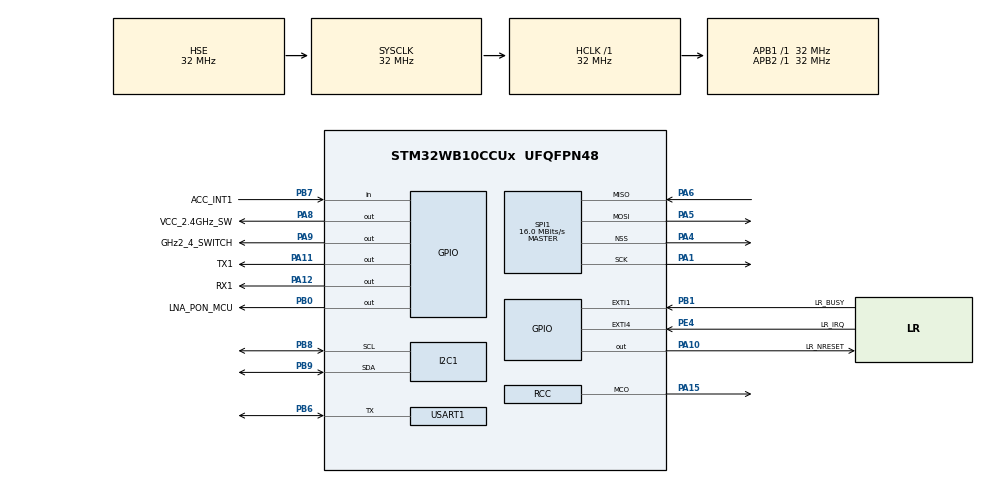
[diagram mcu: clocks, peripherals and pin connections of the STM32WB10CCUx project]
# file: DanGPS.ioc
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ADC1.Channel-0\#ChannelRegularConversion=ADC_CHANNEL_VBAT
ADC1.NbrOfConversionFlag=1
ADC1.Rank-0\#ChannelRegularConversion=1
ADC1.SamplingTime-0\#ChannelRegularConversion=ADC_SAMPLINGTIME_COMMON_1
ADC1.SelectedChannel=ADC_CHANNEL_TEMPSENSOR|ADC_CHANNEL_VBAT
ADC1.master=1
AES2.Algorithm=CRYP_AES_CCM
I2C1.Timing=0x00707CBB
Mcu.Family=STM32WB
Mcu.Name=STM32WB10CCUx
Mcu.Package=UFQFPN48
NVIC.HSEM_IRQn=true\:0\:0\:false\:false\:true\:false\:true\:true
NVIC.IPCC_C1_RX_IRQn=true\:0\:0\:false\:false\:true\:true\:true\:true
NVIC.IPCC_C1_TX_IRQn=true\:0\:0\:false\:false\:true\:true\:true\:true
NVIC.PriorityGroup=NVIC_PRIORITYGROUP_4
OSC_IN.Mode=HSE-External-Oscillator
OSC_IN.Signal=RCC_OSC_IN
OSC_OUT.Mode=HSE-External-Oscillator
OSC_OUT.Signal=RCC_OSC_OUT
PA1.Mode=Full_Duplex_Master
PA1.Signal=SPI1_SCK
PA10.GPIO_Label=LR_NRESET
PA10.PinState=GPIO_PIN_SET
PA10.Signal=GPIO_Output
PA11.GPIO_Label=TX1
PA11.PinState=GPIO_PIN_SET
PA11.Signal=GPIO_Output
PA12.GPIO_Label=RX1
PA12.Signal=GPIO_Output
PA13.Mode=Trace_Asynchronous_SW
PA13.Signal=SYS_JTMS-SWDIO
PA14.Mode=Trace_Asynchronous_SW
PA14.Signal=SYS_JTCK-SWCLK
PA15.Mode=Clock-out
PA15.Signal=RCC_MCO
PA2.Mode=Clock-out-LSCO
PA2.Signal=RCC_LSCO
PA4.Mode=NSS_Signal_Hard_Output
PA4.Signal=SPI1_NSS
PA5.Mode=Full_Duplex_Master
PA5.Signal=SPI1_MOSI
PA6.Mode=Full_Duplex_Master
PA6.Signal=SPI1_MISO
PA8.GPIO_Label=VCC_2.4GHz_SW
PA8.Signal=GPIO_Output
PA9.GPIO_Label=GHz2_4_SWITCH
PA9.Signal=GPIO_Output
PB0.GPIO_Label=LNA_PON_MCU
PB0.Signal=GPIO_Output
PB1.GPIO_Label=LR_BUSY
PB1.Signal=GPXTI1
PB3.Mode=Trace_Asynchronous_SW
PB3.Signal=SYS_JTDO-SWO
PB6.Mode=Half_duplex(single_wire_mode)
PB6.Signal=USART1_TX
PB7.GPIO_Label=ACC_INT1
PB7.Signal=GPIO_Input
PB8.Mode=I2C
PB8.Signal=I2C1_SCL
PB9.Mode=I2C
PB9.Signal=I2C1_SDA
PC14-OSC32_IN.Mode=LSE-External-Oscillator
PC14-OSC32_IN.Signal=RCC_OSC32_IN
PC15-OSC32_OUT.Mode=LSE-External-Oscillator
PC15-OSC32_OUT.Signal=RCC_OSC32_OUT
PE4.GPIO_Label=LR_IRQ
PE4.Signal=GPXTI4
ProjectManager.HeapSize=0x200
ProjectManager.StackSize=0x400
ProjectManager.TargetToolchain=EWARM V9.20
RCC.ADCFreq_Value=32000000
RCC.AHBFreq_Value=32000000
RCC.APB1Freq_Value=32000000
RCC.APB1TimFreq_Value=32000000
RCC.APB2Freq_Value=32000000
RCC.APB2TimFreq_Value=32000000
RCC.APB3Freq_Value=16000000
RCC.CK48CLockSelection=RCC_USBCLKSOURCE_PLL
RCC.CortexFreq_Value=32000000
RCC.HCLKFreq_Value=32000000
RCC.HSE_VALUE=32000000
RCC.HSI_VALUE=16000000
RCC.LSCOSource1=RCC_LSCOSOURCE_LSE
RCC.LSISource1=RCC_LSCOSOURCE_LSI2
RCC.MSIClockRange=RCC_MSIRANGE_11
RCC.PLLM=RCC_PLLM_DIV3
RCC.RCC_MCO1Source=RCC_MCO1SOURCE_HSE
RCC.RFWKPClockSelection=RCC_RFWKPCLKSOURCE_LSE
RCC.RNGCLockSelection=RCC_RNGCLKSOURCE_CLK48
RCC.RTCClockSelection=RCC_RTCCLKSOURCE_LSE
RCC.SYSCLKFreq_VALUE=32000000
RCC.SYSCLKSource=RCC_SYSCLKSOURCE_HSE
RCC.VCOOutputFreq_Value=128000000
RF1.Mode=RF1_Activate
RF1.Signal=RF_RF1
SPI1.BaudRatePrescaler=SPI_BAUDRATEPRESCALER_2
SPI1.CalculateBaudRate=16.0 MBits/s
SPI1.Direction=SPI_DIRECTION_2LINES
SPI1.Mode=SPI_MODE_MASTER
SPI1.VirtualNSS=VM_NSSHARD
SPI1.VirtualType=VM_MASTER
STM32_WPAN.BLE_APPLICATION_TYPE=BLE_SERVER_PROFILE
STM32_WPAN.BLE_DBG_APP_EN=1
STM32_WPAN.BLE_DBG_P2P_STM_EN=1
STM32_WPAN.BLE_STACK=FULL
STM32_WPAN.CFG_ADV_BD_ADDRESS=0x7257acd87a6c
STM32_WPAN.CFG_BLE_MAX_TX_POWER=20
STM32_WPAN.CFG_IO_CAPABILITY=CFG_IO_CAPABILITY_DISPLAY_ONLY
STM32_WPAN.CFG_LPM_SUPPORTED=1
STM32_WPAN.CFG_SC_SUPPORT=CFG_SECURE_MANDATORY
STM32_WPAN.CUSTOM_TEMPLATE=Enabled
STM32_WPAN.INCLUDE_AD_TYPE_16_BIT_SERV_UUID_CMPLT_LIST=0
STM32_WPAN.INCLUDE_AD_TYPE_SHORTENED_LOCAL_NAME=1
STM32_WPAN.INCLUDE_AD_TYPE_TX_POWER_LEVEL=1
STM32_WPAN.NUMBER_OF_SERVICES=1
STM32_WPAN.PAIRING_PARAMETERS=ON
STM32_WPAN.SERVICE1_CHAR1_LONG_NAME=readvar
STM32_WPAN.SERVICE1_CHAR1_SHORT_NAME=cvar
STM32_WPAN.SERVICE1_LONG_NAME=otas
STM32_WPAN.SERVICE1_SHORT_NAME=ota
USART1.VirtualMode-Half_duplex(single_wire_mode)=VM_ASYNC
VP_ADC1_TempSens_Input.Mode=IN-TempSens
VP_ADC1_Vbat_Input.Mode=IN-Vbat
VP_AES2_VS_AES.Mode=AES_Activate
VP_CRC_VS_CRC.Mode=CRC_Activate
VP_HSEM_VS_HSEM.Mode=HSEM_Activate
VP_IPCC_VS_IPCC.Mode=IPCC_Activate
VP_LPTIM1_VS_LPTIM_counterModeInternalClock.Mode=Counts__internal_clock_event_00
VP_PKA_VS_PKA.Mode=PKA_Activate
VP_RTC_VS_RTC_Activate.Mode=RTC_Enabled
VP_RTC_VS_RTC_Calendar.Mode=RTC_Calendar
VP_SEQUENCER_VS_SEQUENCER.Mode=SEQUENCER_Enabled
VP_STM32_WPAN_VS_BLE_HOST.Mode=STM32_WPAN_Enabled
VP_SYS_V_PVD_IN.Mode=Mode_PVD_Int
VP_TINY_LPM_VS_TINY_LPM.Mode=TINY_LPM_Enabled
board=custom

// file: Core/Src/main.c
/* USER CODE BEGIN Header */
/**
  ******************************************************************************
  * @file           : main.c
  * @brief          : Main program body
  ******************************************************************************
  * @attention
  *
  * <h2><center>&copy; Copyright (c) 2021 STMicroelectronics.
  * All rights reserved.</center></h2>
  *
  * This software component is licensed by ST under Ultimate Liberty license
  * SLA0044, the "License"; You may not use this file except in compliance with
  * the License. You may obtain a copy of the License at:
  *                             www.st.com/SLA0044
  *
  ******************************************************************************
  */
/* USER CODE END Header */
#include "main.h"
#include "adc.h"
#include "aes.h"
#include "crc.h"
#include "i2c.h"
#include "ipcc.h"
#include "lptim.h"
#include "pka.h"
#include "rf.h"
#include "rtc.h"
#include "spi.h"
#include "usart.h"
#include "gpio.h"

/* USER CODE BEGIN Includes */
#include "dantag_lr1110.h"
/* USER CODE END Includes */

void SystemClock_Config(void);
void PeriphCommonClock_Config(void);

int main(void)
{
  /* USER CODE BEGIN 1 */
  CoreDebug->DEMCR |= CoreDebug_DEMCR_TRCENA_Msk;
  DWT->CYCCNT = 0;
  DWT->CTRL |= DWT_CTRL_CYCCNTENA_Msk;
  LL_DBGMCU_DisableDBGSleepMode();
  LL_DBGMCU_DisableDBGStopMode();
  LL_DBGMCU_DisableDBGStandbyMode();
  /* USER CODE END 1 */

  /* MCU Configuration--------------------------------------------------------*/

  /* Reset of all peripherals, Initializes the Flash interface and the Systick. */
  HAL_Init();
  /* Config code for STM32_WPAN (HSE Tuning must be done before system clock configuration) */
  MX_APPE_Config();

  /* Configure the system clock */
  SystemClock_Config();

/* Configure the peripherals common clocks */
  PeriphCommonClock_Config();

  /* IPCC initialisation */
  MX_IPCC_Init();

  /* Initialize all configured peripherals */
  MX_GPIO_Init();
  MX_ADC1_Init();
  MX_CRC_Init();
  MX_RTC_Init();
  MX_SPI1_Init();
  MX_I2C1_Init();
  MX_LPTIM1_Init();
  MX_USART1_UART_Init();
  MX_AES2_Init();
  MX_PKA_Init();
  MX_RF_Init();
  /* USER CODE BEGIN 2 */
  /// \todo fix lr1110 struct pin definition
  lr1110_Init();
  /* USER CODE END 2 */

  /* Init code for STM32_WPAN */
  //MX_APPE_Init();

  /* Infinite loop */
  /* USER CODE BEGIN WHILE */
  while (1)
  {
    //lr1110_MainLoop();
    /* USER CODE END WHILE */
    //MX_APPE_Process();

  }
}

void SystemClock_Config(void)
{
  RCC_OscInitTypeDef RCC_OscInitStruct = {0};
  RCC_ClkInitTypeDef RCC_ClkInitStruct = {0};

  /** Configure LSE Drive Capability
  */
  HAL_PWR_EnableBkUpAccess();
  __HAL_RCC_LSEDRIVE_CONFIG(RCC_LSEDRIVE_MEDIUMHIGH);

  /** Initializes the RCC Oscillators according to the specified parameters
  * in the RCC_OscInitTypeDef structure.
  */
  RCC_OscInitStruct.OscillatorType = RCC_OSCILLATORTYPE_HSI|RCC_OSCILLATORTYPE_HSE
                              |RCC_OSCILLATORTYPE_LSE;
  RCC_OscInitStruct.HSEState = RCC_HSE_ON;
  RCC_OscInitStruct.LSEState = RCC_LSE_ON;
  RCC_OscInitStruct.HSIState = RCC_HSI_ON;
  RCC_OscInitStruct.HSICalibrationValue = RCC_HSICALIBRATION_DEFAULT;
  RCC_OscInitStruct.PLL.PLLState = RCC_PLL_NONE;
  if (HAL_RCC_OscConfig(&RCC_OscInitStruct) != HAL_OK)
  {
    Error_Handler();
  }

  /** Configure the SYSCLKSource, HCLK, PCLK1 and PCLK2 clocks dividers
  */
  RCC_ClkInitStruct.ClockType = RCC_CLOCKTYPE_HCLK4|RCC_CLOCKTYPE_HCLK2
                              |RCC_CLOCKTYPE_HCLK|RCC_CLOCKTYPE_SYSCLK
                              |RCC_CLOCKTYPE_PCLK1|RCC_CLOCKTYPE_PCLK2;
  RCC_ClkInitStruct.SYSCLKSource = RCC_SYSCLKSOURCE_HSE;
  RCC_ClkInitStruct.AHBCLKDivider = RCC_SYSCLK_DIV1;
  RCC_ClkInitStruct.APB1CLKDivider = RCC_HCLK_DIV1;
  RCC_ClkInitStruct.APB2CLKDivider = RCC_HCLK_DIV1;
  RCC_ClkInitStruct.AHBCLK2Divider = RCC_SYSCLK_DIV1;
  RCC_ClkInitStruct.AHBCLK4Divider = RCC_SYSCLK_DIV1;

  if (HAL_RCC_ClockConfig(&RCC_ClkInitStruct, FLASH_LATENCY_1) != HAL_OK)
  {
    Error_Handler();
  }
  HAL_RCC_MCOConfig(RCC_MCO1, RCC_MCO1SOURCE_HSE, RCC_MCODIV_1);
  HAL_RCCEx_EnableLSCO(RCC_LSCOSOURCE_LSE);
}

void PeriphCommonClock_Config(void)
{
  RCC_PeriphCLKInitTypeDef PeriphClkInitStruct = {0};

  /** Initializes the peripherals clock
  */
  PeriphClkInitStruct.PeriphClockSelection = RCC_PERIPHCLK_RFWAKEUP;
  PeriphClkInitStruct.RFWakeUpClockSelection = RCC_RFWKPCLKSOURCE_LSE;
  if (HAL_RCCEx_PeriphCLKConfig(&PeriphClkInitStruct) != HAL_OK)
  {
    Error_Handler();
  }
}

void Error_Handler(void)
{
  /* USER CODE BEGIN Error_Handler_Debug */
  /* User can add his own implementation to report the HAL error return state */
  __disable_irq();
  __ASM("BKPT #0");
  while (1)
  {
  }
  /* USER CODE END Error_Handler_Debug */
}

#ifdef  USE_FULL_ASSERT
/**
  * @brief  Reports the name of the source file and the source line number
  *         where the assert_param error has occurred.
  * @param  file: pointer to the source file name
  * @param  line: assert_param error line source number
  * @retval None
  */
void assert_failed(uint8_t *file, uint32_t line)
{
  /* USER CODE BEGIN 6 */
  __ASM("BKPT #0");
	while(1)
	{}
  /* User can add his own implementation to report the file name and line number,
     ex: printf("Wrong parameters value: file %s on line %d\r\n", file, line) */
  /* USER CODE END 6 */
}
#endif /* USE_FULL_ASSERT */
